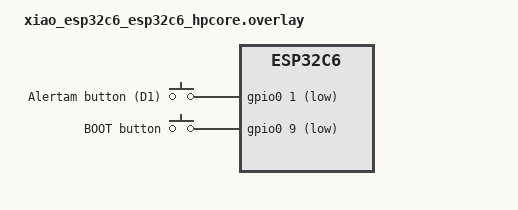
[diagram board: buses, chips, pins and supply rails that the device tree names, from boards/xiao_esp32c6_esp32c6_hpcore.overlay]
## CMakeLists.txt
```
cmake_minimum_required(VERSION 3.20.0)

find_package(Zephyr REQUIRED HINTS $ENV{ZEPHYR_BASE})
project(bitchat_esp32c6)

target_sources(app PRIVATE 
    src/main.c
    src/bitchat_crypto.c
    src/bitchat_wire.c
    src/noise_xx.c
    src/gesture.c
    src/alert_retry.c
    src/alertam.c
    src/alertam_store.c
    src/alertam_record.c
    lib/monocypher/monocypher.c
    lib/monocypher/monocypher-ed25519.c
)
```

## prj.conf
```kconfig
# Covekey Project Configuration - BitChat Bot

# Console and Logging
CONFIG_LOG=y
CONFIG_LOG_MODE_IMMEDIATE=y
CONFIG_LOG_DEFAULT_LEVEL=3
CONFIG_CONSOLE=y
CONFIG_UART_CONSOLE=y
CONFIG_SERIAL=y
CONFIG_PRINTK=y
CONFIG_EARLY_CONSOLE=y

# GPIO (required for future expansion)
CONFIG_GPIO=y

# Bluetooth LE Support
CONFIG_BT=y
CONFIG_BT_PERIPHERAL=y
CONFIG_BT_CENTRAL=y
CONFIG_BT_OBSERVER=y
CONFIG_BT_BROADCASTER=y
CONFIG_BT_DEVICE_NAME="BitChat"
CONFIG_BT_DEVICE_NAME_DYNAMIC=n
CONFIG_BT_MAX_CONN=4
CONFIG_BT_L2CAP_TX_BUF_COUNT=3
CONFIG_BT_CONN_CHECK_NULL_BEFORE_CREATE=y

# ESP32-C6 CRITICAL: Enable parallel scan and connection initiation
# bt_le_scan_stop() crashes on ESP32-C6, this allows connections while scanning
CONFIG_BT_SCAN_AND_INITIATE_IN_PARALLEL=y

# GATT Client support (for mesh messaging)
CONFIG_BT_GATT_CLIENT=y
# Alertam: find the peer's CCC descriptor instead of guessing its handle
CONFIG_BT_GATT_AUTO_DISCOVER_CCC=y

# MTU and buffer configuration
# Increased ACL buffer size to support higher ATT MTU negotiation
# ATT MTU is negotiated based on ACL buffer size, not L2CAP MTU
# 512 bytes allows ATT MTU of ~508 bytes, preventing fragmentation of TLV handshakes
CONFIG_BT_L2CAP_TX_MTU=512
CONFIG_BT_BUF_ACL_TX_SIZE=512
CONFIG_BT_BUF_ACL_RX_SIZE=512
CONFIG_BT_ATT_PREPARE_COUNT=1

# HCI buffer pool - increased for parallel scan+connect operations
CONFIG_BT_BUF_ACL_TX_COUNT=4

# BLE advertising - extended advertising required for parallel scan/initiate
# CONFIG_BT_EXT_ADV is auto-enabled by CONFIG_BT_SCAN_AND_INITIATE_IN_PARALLEL
CONFIG_BT_PRIVACY=n

# NO NETWORKING - Bluetooth only
CONFIG_NETWORKING=n

# PSA Crypto API (modern mbedTLS) for Noise XX protocol
CONFIG_MBEDTLS=y
CONFIG_MBEDTLS_BUILTIN=y
CONFIG_PSA_CRYPTO_PROVIDER_MBEDTLS=y
CONFIG_PSA_WANT_ALG_ECDH=y
CONFIG_PSA_WANT_ALG_SHA_256=y
CONFIG_PSA_WANT_ALG_HMAC=y
# Noise_XX requires ChaCha20-Poly1305, not AES-GCM
CONFIG_PSA_WANT_ALG_CHACHA20_POLY1305=y
CONFIG_PSA_WANT_KEY_TYPE_CHACHA20=y
# Noise_XX requires Curve25519 (X25519), not secp256r1
CONFIG_PSA_WANT_ECC_MONTGOMERY_255=y
CONFIG_PSA_WANT_KEY_TYPE_ECC_KEY_PAIR_IMPORT=y
CONFIG_PSA_WANT_KEY_TYPE_ECC_KEY_PAIR_EXPORT=y
CONFIG_PSA_WANT_KEY_TYPE_ECC_KEY_PAIR_GENERATE=y
CONFIG_MBEDTLS_ENABLE_HEAP=y
CONFIG_MBEDTLS_HEAP_SIZE=40960

# Shell for interactive control
CONFIG_SHELL=y
CONFIG_SHELL_BACKEND_SERIAL=y
CONFIG_SHELL_PROMPT_UART="bitchat> "
CONFIG_SHELL_CMD_BUFF_SIZE=256
CONFIG_SHELL_ARGC_MAX=12

# Memory and Threading
CONFIG_MAIN_STACK_SIZE=8192
CONFIG_SYSTEM_WORKQUEUE_STACK_SIZE=8192
CONFIG_HEAP_MEM_POOL_SIZE=65536

# ESP32-C6 BLE soft controller stability - increased buffers
CONFIG_BT_BUF_EVT_RX_COUNT=16
CONFIG_BT_BUF_CMD_TX_COUNT=8
CONFIG_BT_RX_STACK_SIZE=4096

# CRITICAL: Extended advertising/scanning buffer size limits for ESP32-C6
# When CONFIG_BT_SCAN_AND_INITIATE_IN_PARALLEL=y, BT_EXT_ADV is auto-enabled
# Extended advertising scan reports require 122 bytes for HCI event buffers
# ESP32-C6 ACL data buffers limited to 58 bytes, but event buffers can be larger
CONFIG_BT_BUF_EVT_DISCARDABLE_SIZE=122
CONFIG_BT_BUF_EVT_DISCARDABLE_COUNT=8
CONFIG_BT_BUF_EVT_RX_SIZE=122

# System
CONFIG_REBOOT=y

# Alertam persistence: identity, nickname, circle, SOS text (src/alertam_store.c)
# Zephyr settings on ZMS in storage_partition (0x3B0000). Not encrypted yet.
CONFIG_FLASH=y
CONFIG_FLASH_MAP=y
CONFIG_ZMS=y
CONFIG_SETTINGS=y
CONFIG_SETTINGS_ZMS=y
CONFIG_SETTINGS_ZMS_CUSTOM_SECTOR_COUNT=y
CONFIG_SETTINGS_ZMS_SECTOR_COUNT=8

# BLE TX power: default was 0 dBm; +9 dBm is Espressif's default (max +20).
CONFIG_BT_CTLR_TX_PWR_PLUS_9=y
```

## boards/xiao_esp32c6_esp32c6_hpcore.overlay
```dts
/*
 * Alertam buttons on the Seeed XIAO ESP32-C6.
 *
 * - alertam_btn: external tactile button between D1 (GPIO1) and GND,
 *   internal pull-up, active low. This is the "real" panic button.
 * - boot_btn: the on-board BOOT button (GPIO9, has an external pull-up).
 *   Same gestures, so the firmware can be tested without wiring anything.
 *
 * Both feed the same gesture detector (src/gesture.c).
 */
/ {
	alertam_buttons {
		compatible = "gpio-keys";

		alertam_btn: alertam_button {
			gpios = <&gpio0 1 (GPIO_ACTIVE_LOW | GPIO_PULL_UP)>;
			label = "Alertam button (D1)";
		};

		boot_btn: boot_button {
			gpios = <&gpio0 9 GPIO_ACTIVE_LOW>;
			label = "BOOT button";
		};
	};

	aliases {
		alertam-button = &alertam_btn;
		alertam-boot-button = &boot_btn;
	};
};
```

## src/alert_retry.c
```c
/*
 * alert_retry.c - retry / re-broadcast scheduling for Alertam alerts.
 * See alert_retry.h.
 */
#include "alert_retry.h"

#include <string.h>

/* ---------- public alert ---------- */

bool ar_pub_fresh(const struct ar_public *p, int64_t now)
{
	return p->have_packet && now - p->built < AR_PUB_STALE_MS;
}

void ar_pub_start(struct ar_public *p, int64_t now, bool keep_packet)
{
	if (keep_packet && p->state != AR_PUB_IDLE && ar_pub_fresh(p, now)) {
		/* Same alert again: extend it, send right away, no new chat line */
		p->started = now;
		if (p->state == AR_PUB_SENT) {
			p->first_sent = now;
		}
		p->last_try = -1;
		return;
	}
	memset(p, 0, sizeof(*p));
	p->state = AR_PUB_PENDING;
	p->started = now;
	p->last_try = -1;
}

void ar_pub_stop(struct ar_public *p)
{
	p->state = AR_PUB_IDLE;
}

enum ar_action ar_pub_poll(struct ar_public *p, int64_t now, bool can_send, bool new_link)
{
	if (p->state == AR_PUB_IDLE) {
		return AR_NONE;
	}
	if (p->state == AR_PUB_SENT && now - p->first_sent >= AR_LIFETIME_MS) {
		p->state = AR_PUB_IDLE;
		return AR_NONE;
	}
	if (!can_send) {
		return AR_NONE;
	}
	bool fresh = ar_pub_fresh(p, now);
	bool never = p->last_try < 0;

	if (p->state == AR_PUB_PENDING) {
		if (!fresh) {
			return AR_REBUILD_SEND; /* nothing cached yet, or about to go stale */
		}
		if (never || new_link || now - p->last_try >= AR_PUB_RETRY_MS) {
			return AR_SEND;
		}
		return AR_NONE;
	}
	/* SENT */
	if (fresh) {
		if (never || new_link || now - p->last_try >= AR_PUB_REBROADCAST_MS) {
			return AR_SEND;
		}
		return AR_NONE;
	}
	/* Re-broadcast window over: only a phone that just came into range is
	 * worth a new (re-signed) packet */
	return new_link || never ? AR_REBUILD_SEND : AR_NONE;
}

void ar_pub_built(struct ar_public *p, int64_t now)
{
	p->have_packet = true;
	p->built = now;
	p->builds++;
}

bool ar_pub_wrote(struct ar_public *p, int64_t now, bool ok)
{
	p->last_try = now;
	if (!ok) {
		return false;
	}
	p->writes++;
	if (p->state == AR_PUB_PENDING) {
		p->state = AR_PUB_SENT;
		p->first_sent = now;
		return true;
	}
	return false;
}

/* ---------- private SOS ---------- */

int64_t ar_pm_backoff(uint32_t n)
{
	int64_t d = AR_PM_BACKOFF_MIN_MS;
	for (uint32_t i = 1; i < n && d < AR_PM_BACKOFF_MAX_MS; i++) {
		d *= 2;
	}
	return d > AR_PM_BACKOFF_MAX_MS ? AR_PM_BACKOFF_MAX_MS : d;
}

static bool undelivered(const struct ar_rcpt *r)
{
	return r->state == AR_RCPT_PENDING || r->state == AR_RCPT_SENT;
}

void ar_priv_start(struct ar_private *p, int64_t now, int n)
{
	memset(p, 0, sizeof(*p));
	p->n = n > AR_MAX_RCPT ? AR_MAX_RCPT : (n < 0 ? 0 : n);
	p->active = p->n > 0;
	p->started = now;
	for (int i = 0; i < p->n; i++) {
		p->r[i].state = AR_RCPT_PENDING;
		p->r[i].next = now;
		p->r[i].last_try = -1;
	}
}

void ar_priv_restart(struct ar_private *p, int64_t now)
{
	p->started = now;
	for (int i = 0; i < p->n; i++) {
		struct ar_rcpt *r = &p->r[i];
		if (r->state == AR_RCPT_EXPIRED) {
			r->state = r->attempts ? AR_RCPT_SENT : AR_RCPT_PENDING;
		}
		if (undelivered(r)) {
			r->next = now;
			r->attempts = 0; /* backoff starts over */
		}
	}
	p->active = ar_priv_count(p, AR_RCPT_PENDING) + ar_priv_count(p, AR_RCPT_SENT) > 0;
}

void ar_priv_stop(struct ar_private *p)
{
	p->active = false;
}

int ar_priv_tick(struct ar_private *p, int64_t now)
{
	if (!p->active) {
		return 0;
	}
	int expired = 0;
	if (now - p->started >= AR_LIFETIME_MS) {
		for (int i = 0; i < p->n; i++) {
			if (undelivered(&p->r[i])) {
				p->r[i].state = AR_RCPT_EXPIRED;
				expired++;
			}
		}
	}
	bool left = false;
	for (int i = 0; i < p->n; i++) {
		left |= undelivered(&p->r[i]);
	}
	p->active = left;
	return expired;
}

bool ar_priv_due(const struct ar_private *p, int i, int64_t now, bool can_send)
{
	return p->active && can_send && i >= 0 && i < p->n && undelivered(&p->r[i]) &&
	       now >= p->r[i].next;
}

void ar_priv_attempted(struct ar_private *p, int i, int64_t now, bool ok)
{
	struct ar_rcpt *r = &p->r[i];
	r->last_try = now;
	if (ok) {
		r->attempts++;
		if (r->state == AR_RCPT_PENDING) {
			r->state = AR_RCPT_SENT;
		}
		r->next = now + ar_pm_backoff(r->attempts);
	} else {
		/* local failure (link dropped, encrypt error): short retry, no backoff */
		r->failures++;
		r->next = now + AR_PM_BACKOFF_MIN_MS;
	}
}

void ar_priv_link_up(struct ar_private *p, int64_t now)
{
	for (int i = 0; p->active && i < p->n; i++) {
		struct ar_rcpt *r = &p->r[i];
		if (undelivered(r) && r->next > now &&
		    (r->last_try < 0 || now - r->last_try >= AR_PM_KICK_GAP_MS)) {
			r->next = now;
		}
	}
}

bool ar_priv_ack(struct ar_private *p, int i, int64_t now)
{
	if (i < 0 || i >= p->n || p->r[i].state == AR_RCPT_DELIVERED ||
	    p->r[i].state == AR_RCPT_UNUSED) {
		return false;
	}
	/* A late ACK after expiry still counts: the message did arrive */
	p->r[i].state = AR_RCPT_DELIVERED;
	p->r[i].delivered_at = now;
	return true;
}

int64_t ar_priv_next_due(const struct ar_private *p)
{
	int64_t best = -1;
	for (int i = 0; p->active && i < p->n; i++) {
		if (undelivered(&p->r[i]) && (best < 0 || p->r[i].next < best)) {
			best = p->r[i].next;
		}
	}
	return best;
}

int ar_priv_count(const struct ar_private *p, enum ar_rcpt_state s)
{
	int c = 0;
	for (int i = 0; i < p->n; i++) {
		c += p->r[i].state == s;
	}
	return c;
}

const char *ar_pub_state_name(enum ar_pub_state s)
{
	switch (s) {
	case AR_PUB_PENDING: return "pending";
	case AR_PUB_SENT:    return "sent";
	default:             return "idle";
	}
}

const char *ar_rcpt_state_name(enum ar_rcpt_state s)
{
	switch (s) {
	case AR_RCPT_PENDING:   return "pending";
	case AR_RCPT_SENT:      return "sent, waiting ACK";
	case AR_RCPT_DELIVERED: return "delivered";
	case AR_RCPT_EXPIRED:   return "EXPIRED";
	default:                return "-";
	}
}
```

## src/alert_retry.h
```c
/*
 * alert_retry.h - retry / re-broadcast scheduling for Alertam alerts
 *
 * Pure state machines (no Zephyr, no I/O): the caller feeds a millisecond
 * clock and whether it can send right now (a link is ready and the wall clock
 * is synced), and gets back what to do. Unit-tested on the host
 * (tests/test_alert_retry.c).
 *
 * Public alert (signed broadcast, no ACK exists):
 *   PENDING  nothing written to any link yet. Retry every AR_PUB_RETRY_MS and
 *            on every new link; rebuild the signed packet whenever the cached
 *            one is AR_PUB_STALE_MS old (the app rejects |skew| > 120 s).
 *   SENT     written to at least one link. Re-send the same cached bytes every
 *            AR_PUB_REBROADCAST_MS until the cache is stale (the app dedups
 *            identical packets, so phones that already have it see nothing new).
 *            After that, only a new link triggers a rebuild + send (a rebuild is
 *            a new chat line). Ends AR_LIFETIME_MS after the first write.
 *   A PENDING alert never expires: it must go out at least once.
 *
 * Private SOS (Noise PM per circle member, the app ACKs with the messageID):
 *   PENDING -> SENT (written, waiting for the ACK) -> DELIVERED, or EXPIRED
 *   AR_LIFETIME_MS after the SOS started. Undelivered recipients are retried
 *   with backoff 5, 10, 20, 30, 30... s, each one on its own schedule.
 */
#ifndef ALERT_RETRY_H
#define ALERT_RETRY_H

#include <stdbool.h>
#include <stdint.h>

#define AR_PUB_RETRY_MS        5000
#define AR_PUB_REBROADCAST_MS 20000
#define AR_PUB_STALE_MS      100000
#define AR_LIFETIME_MS       600000
#define AR_PM_BACKOFF_MIN_MS   5000
#define AR_PM_BACKOFF_MAX_MS  30000
#define AR_PM_KICK_GAP_MS      2000 /* min gap between attempts when a link comes up */
#define AR_MAX_RCPT 5

enum ar_action {
	AR_NONE = 0,
	AR_SEND,         /* write the cached packet */
	AR_REBUILD_SEND, /* build a fresh signed packet, cache it, write it */
};

/* ---------- public alert ---------- */

enum ar_pub_state {
	AR_PUB_IDLE = 0,
	AR_PUB_PENDING,
	AR_PUB_SENT,
};

struct ar_public {
	enum ar_pub_state state;
	bool have_packet;
	int64_t started;    /* trigger time */
	int64_t built;      /* build time of the cached packet */
	int64_t first_sent; /* first successful write (lifetime anchor) */
	int64_t last_try;   /* last write attempt, -1 = none since (re)start */
	uint32_t writes;    /* successful writes */
	uint32_t builds;
};

/* Start an alert. keep_packet: a re-trigger with the same text keeps a still
 * fresh cached packet (no duplicate chat line) and just refreshes the lifetime
 * and forces an immediate send. */
void ar_pub_start(struct ar_public *p, int64_t now, bool keep_packet);
void ar_pub_stop(struct ar_public *p);
/* Decide what to do now. new_link: a link just became usable. Also ends the
 * alert when its lifetime is over (state goes back to IDLE). */
enum ar_action ar_pub_poll(struct ar_public *p, int64_t now, bool can_send, bool new_link);
void ar_pub_built(struct ar_public *p, int64_t now);
/* Result of the write the last poll asked for. Returns true on the first
 * successful write (PENDING -> SENT). */
bool ar_pub_wrote(struct ar_public *p, int64_t now, bool ok);
bool ar_pub_fresh(const struct ar_public *p, int64_t now);

/* ---------- private SOS ---------- */

enum ar_rcpt_state {
	AR_RCPT_UNUSED = 0,
	AR_RCPT_PENDING,   /* never written */
	AR_RCPT_SENT,      /* written at least once, no ACK yet */
	AR_RCPT_DELIVERED, /* ACK received */
	AR_RCPT_EXPIRED,   /* lifetime over without an ACK */
};

struct ar_rcpt {
	enum ar_rcpt_state state;
	uint32_t attempts;  /* successful writes */
	uint32_t failures;  /* writes that failed locally */
	int64_t next;       /* next attempt due at */
	int64_t last_try;
	int64_t delivered_at;
};

struct ar_private {
	bool active;
	int64_t started;
	int n;
	struct ar_rcpt r[AR_MAX_RCPT];
};

/* Backoff after the n-th successful attempt (n >= 1) */
int64_t ar_pm_backoff(uint32_t n);

void ar_priv_start(struct ar_private *p, int64_t now, int n);
/* Re-trigger: refresh the lifetime and make every undelivered recipient due now */
void ar_priv_restart(struct ar_private *p, int64_t now);
void ar_priv_stop(struct ar_private *p);
/* Lifetime / completion bookkeeping. Returns the number of recipients that
 * just expired (so the caller can log them). Clears active when done. */
int ar_priv_tick(struct ar_private *p, int64_t now);
bool ar_priv_due(const struct ar_private *p, int i, int64_t now, bool can_send);
void ar_priv_attempted(struct ar_private *p, int i, int64_t now, bool ok);
/* A link came up: pull undelivered retries forward (not more often than
 * AR_PM_KICK_GAP_MS per recipient). */
void ar_priv_link_up(struct ar_private *p, int64_t now);
/* ACK for recipient i. Returns true if this is the first one. */
bool ar_priv_ack(struct ar_private *p, int i, int64_t now);
/* Earliest time any undelivered recipient is due (or -1 if none) */
int64_t ar_priv_next_due(const struct ar_private *p);
int ar_priv_count(const struct ar_private *p, enum ar_rcpt_state s);

const char *ar_pub_state_name(enum ar_pub_state s);
const char *ar_rcpt_state_name(enum ar_rcpt_state s);

#endif /* ALERT_RETRY_H */
```

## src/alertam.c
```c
/*
 * alertam.c - Alertam panic-button behavior. See alertam.h.
 */
#include "alertam.h"

#include <string.h>
#include <zephyr/drivers/gpio.h>
#include <stdlib.h>
#include <zephyr/init.h>
#include <esp_bt.h>
#include <zephyr/shell/shell.h>
#include <zephyr/sys/printk.h>

#include "alert_retry.h"
#include "alertam_store.h"
#include "bitchat_wire.h"
#include "gesture.h"

#define CIRCLE_MAX 5
#define POLL_MS 10

static const struct gpio_dt_spec btn_ext = GPIO_DT_SPEC_GET(DT_ALIAS(alertam_button), gpios);
static const struct gpio_dt_spec btn_boot = GPIO_DT_SPEC_GET(DT_ALIAS(alertam_boot_button), gpios);
static const struct gpio_dt_spec led = GPIO_DT_SPEC_GET(DT_ALIAS(led0), gpios);

static struct k_work_q *ble_q;
static alertam_links_fn links_ready;

static char sos_text[200] = "SOS - Alertam: necesito ayuda";

static struct {
	bool used;
	char name[24];  /* nickname at the time it was added */
	char id_hex[17];
} circle[CIRCLE_MAX];

/* ---------- alerts (run on the BLE work queue) ----------
 *
 * Nothing is fire-and-forget: both alerts stay active and are retried by
 * retry_work (1 s tick while anything is active) until delivered, see
 * alert_retry.h for the rules. State is shared with the shell ('sos status',
 * 'sos cancel'), hence alert_lock. */

#define RETRY_TICK_MS 1000

BUILD_ASSERT(CIRCLE_MAX <= AR_MAX_RCPT, "one SOS recipient slot per circle member");

static K_MUTEX_DEFINE(alert_lock);
static atomic_t link_kick; /* a link became usable since the last tick */

static struct ar_public pub;
static char pub_text[sizeof(sos_text)];  /* text the cached packet carries */
static uint8_t pub_pkt[BCW_MAX_PACKET];
static int pub_len;

static struct ar_private priv;
static char priv_text[sizeof(sos_text)];
static struct {
	char name[24];
	char id_hex[17];
	uint8_t id[8];
	char msg_id[37]; /* one per SOS: retries are deduped by the app */
} rcpt[AR_MAX_RCPT];

static void retry_handler(struct k_work *work);
static K_WORK_DELAYABLE_DEFINE(retry_work, retry_handler);

static bool can_send(void)
{
	return bcw_clock_synced() && links_ready && links_ready() > 0;
}

static const char *why_not(void)
{
	return !bcw_clock_synced() ? "no phone seen yet (clock not synced)" : "no phone in range";
}

static void led_confirm(void);

static void public_step(int64_t now, bool ok_to_send, bool new_link)
{
	enum ar_pub_state before = pub.state;
	enum ar_action a = ar_pub_poll(&pub, now, ok_to_send, new_link);

	if (before == AR_PUB_SENT && pub.state == AR_PUB_IDLE) {
		printk("[Alertam] PUBLIC alert finished (%u writes, %u packets, %d min active)\n",
		       pub.writes, pub.builds, AR_LIFETIME_MS / 60000);
		return;
	}
	if (a == AR_NONE) {
		return;
	}
	if (a == AR_REBUILD_SEND) {
		int n = bcw_build_public_message(pub_text, pub_pkt, sizeof(pub_pkt));
		if (n < 0) {
			printk("[Alertam] PUBLIC alert: cannot build packet (%d), dropped\n", n);
			ar_pub_stop(&pub);
			return;
		}
		pub_len = n;
		if (pub.builds > 0) {
			printk("[Alertam] PUBLIC alert re-signed (%s)\n", pub.state == AR_PUB_PENDING
			       ? "cached packet about to go stale" : "phone came into range");
		}
		ar_pub_built(&pub, now);
	}
	int ret = bcw_broadcast(pub_pkt, (uint16_t)pub_len);
	if (ar_pub_wrote(&pub, now, ret == 0)) {
		printk("[Alertam] PUBLIC alert sent (pending %lld s): \"%s\" - re-broadcasting "
		       "every %d s for %d s\n", (now - pub.started) / 1000, pub_text,
		       AR_PUB_REBROADCAST_MS / 1000, AR_PUB_STALE_MS / 1000);
		led_confirm();
	} else if (ret == 0) {
		printk("[Alertam] PUBLIC alert re-broadcast #%u (packet age %lld s)\n",
		       pub.writes - 1, (now - pub.built) / 1000);
	} else {
		printk("[Alertam] PUBLIC alert write failed (%d), retry in %d s\n", ret,
		       AR_PUB_RETRY_MS / 1000);
	}
}

static void private_step(int64_t now, bool ok_to_send, bool new_link)
{
	if (!priv.active) {
		return;
	}
	if (ar_priv_tick(&priv, now) > 0) {
		for (int i = 0; i < priv.n; i++) {
			if (priv.r[i].state == AR_RCPT_EXPIRED) {
				printk("[Alertam] private SOS -> %s: NOT delivered after %u attempts, "
				       "giving up\n", rcpt[i].name, priv.r[i].attempts);
			}
		}
	}
	if (new_link) {
		ar_priv_link_up(&priv, now);
	}
	for (int i = 0; i < priv.n; i++) {
		if (!ar_priv_due(&priv, i, now, ok_to_send)) {
			continue;
		}
		/* one failing member must not block the others */
		int ret = bcw_send_private_with_id(rcpt[i].id_hex, priv_text, rcpt[i].msg_id);
		ar_priv_attempted(&priv, i, now, ret == 0);
		printk("[Alertam] private SOS -> %s: attempt %u %s, next in %lld s\n", rcpt[i].name,
		       priv.r[i].attempts + priv.r[i].failures,
		       ret == 0 ? "sent/queued" : "failed", (priv.r[i].next - now) / 1000);
	}
}

static void retry_handler(struct k_work *work)
{
	int64_t now = k_uptime_get();
	bool new_link = atomic_clear(&link_kick) != 0;
	bool ok_to_send = can_send();

	k_mutex_lock(&alert_lock, K_FOREVER);
	public_step(now, ok_to_send, new_link);
	private_step(now, ok_to_send, new_link);
	bool active = pub.state != AR_PUB_IDLE || priv.active;
	k_mutex_unlock(&alert_lock);

	if (active) {
		k_work_reschedule_for_queue(ble_q, &retry_work, K_MSEC(RETRY_TICK_MS));
	}
}

static void public_alert_handler(struct k_work *work)
{
	int64_t now = k_uptime_get();
	k_mutex_lock(&alert_lock, K_FOREVER);
	bool same = pub.state != AR_PUB_IDLE && strcmp(pub_text, sos_text) == 0;
	if (pub.state != AR_PUB_IDLE) {
		printk("[Alertam] PUBLIC alert re-triggered (%s)\n",
		       same && ar_pub_fresh(&pub, now) ? "same packet, lifetime refreshed"
						       : "new packet");
	}
	ar_pub_start(&pub, now, same);
	strcpy(pub_text, sos_text);
	if (!can_send()) {
		printk("[Alertam] PUBLIC alert pending (%s): \"%s\"\n", why_not(), pub_text);
	}
	k_mutex_unlock(&alert_lock);
	k_work_reschedule_for_queue(ble_q, &retry_work, K_NO_WAIT);
}

/* Is the active SOS for the same text and the same circle? */
static bool same_sos(void)
{
	int n = 0;
	if (!priv.active || strcmp(priv_text, sos_text) != 0) {
		return false;
	}
	for (int i = 0; i < CIRCLE_MAX; i++) {
		if (!circle[i].used) {
			continue;
		}
		bool found = false;
		for (int j = 0; j < priv.n && !found; j++) {
			found = strcmp(rcpt[j].id_hex, circle[i].id_hex) == 0;
		}
		if (!found) {
			return false;
		}
		n++;
	}
	return n == priv.n;
}

static void private_sos_handler(struct k_work *work)
{
	int64_t now = k_uptime_get();
	k_mutex_lock(&alert_lock, K_FOREVER);
	if (same_sos()) {
		ar_priv_restart(&priv, now);
		printk("[Alertam] private SOS re-triggered: %d undelivered retried now\n",
		       ar_priv_count(&priv, AR_RCPT_PENDING) + ar_priv_count(&priv, AR_RCPT_SENT));
	} else {
		/* New SOS: snapshot the circle and the text, one messageID each */
		int n = 0;
		for (int i = 0; i < CIRCLE_MAX; i++) {
			if (!circle[i].used || bcw_lookup_peer(circle[i].id_hex, rcpt[n].id) != 0) {
				continue;
			}
			snprintk(rcpt[n].name, sizeof(rcpt[n].name), "%s", circle[i].name);
			snprintk(rcpt[n].id_hex, sizeof(rcpt[n].id_hex), "%s", circle[i].id_hex);
			bcw_new_message_id(rcpt[n].msg_id);
			n++;
		}
		ar_priv_start(&priv, now, n);
		strcpy(priv_text, sos_text);
		if (n == 0) {
			printk("[Alertam] private SOS: circle is empty (use 'circle add <nick>')\n");
		} else if (!can_send()) {
			printk("[Alertam] private SOS to %d recipient(s) pending (%s)\n", n, why_not());
		} else {
			printk("[Alertam] private SOS to %d recipient(s)\n", n);
		}
	}
	k_mutex_unlock(&alert_lock);
	k_work_reschedule_for_queue(ble_q, &retry_work, K_NO_WAIT);
}

/* Delivered ACK / read receipt from bitchat_wire (BLE work queue) */
static void on_delivered(const uint8_t peer_id[8], const char *msg_id)
{
	int64_t now = k_uptime_get();
	k_mutex_lock(&alert_lock, K_FOREVER);
	for (int i = 0; i < priv.n; i++) {
		if (memcmp(rcpt[i].id, peer_id, 8) != 0 || strcmp(rcpt[i].msg_id, msg_id) != 0) {
			continue;
		}
		if (ar_priv_ack(&priv, i, now)) {
			printk("[Alertam] private SOS -> %s: delivered (%u attempt(s), %lld s)\n",
			       rcpt[i].name, priv.r[i].attempts, (now - priv.started) / 1000);
			if (ar_priv_count(&priv, AR_RCPT_DELIVERED) == priv.n) {
				printk("[Alertam] private SOS: all %d recipient(s) delivered\n", priv.n);
			}
			led_confirm();
		}
		break;
	}
	k_mutex_unlock(&alert_lock);
}

void alertam_link_ready(void)
{
	if (!ble_q) {
		return;
	}
	atomic_set(&link_kick, 1);
	k_work_reschedule_for_queue(ble_q, &retry_work, K_NO_WAIT);
}

static K_WORK_DEFINE(public_alert_work, public_alert_handler);
static K_WORK_DEFINE(private_sos_work, private_sos_handler);

/* ---------- LED feedback ---------- */

static void led_blink(int times, int on_ms, int off_ms)
{
	for (int i = 0; i < times; i++) {
		gpio_pin_set_dt(&led, 1);
		k_msleep(on_ms);
		gpio_pin_set_dt(&led, 0);
		if (i + 1 < times) {
			k_msleep(off_ms);
		}
	}
}

/* Short blink when a delivery is first confirmed. Called from the BLE queue,
 * so it must not sleep: the system work queue turns the LED off. */
static void led_off_handler(struct k_work *work)
{
	gpio_pin_set_dt(&led, 0);
}
static K_WORK_DELAYABLE_DEFINE(led_off_work, led_off_handler);

static void led_confirm(void)
{
	gpio_pin_set_dt(&led, 1);
	k_work_reschedule(&led_off_work, K_MSEC(200));
}

/* ---------- button thread ---------- */

static void button_thread(void *a, void *b, void *c)
{
	struct gesture_state st;
	const struct gesture_cfg cfg = GESTURE_CFG_DEFAULT;
	gesture_init(&st);

	while (1) {
		bool pressed = gpio_pin_get_dt(&btn_ext) > 0 || gpio_pin_get_dt(&btn_boot) > 0;
		enum gesture g = gesture_update(&st, &cfg, pressed, k_uptime_get_32());

		switch (g) {
		case GESTURE_LONG:
			printk("[Button] long press -> PUBLIC alert\n");
			k_work_submit_to_queue(ble_q, &public_alert_work);
			led_blink(1, 1500, 0);
			break;
		case GESTURE_DOUBLE:
			printk("[Button] double tap -> PRIVATE SOS\n");
			k_work_submit_to_queue(ble_q, &private_sos_work);
			led_blink(3, 120, 120);
			break;
		case GESTURE_SINGLE:
			printk("[Button] single tap (no action)\n");
			break;
		default:
			break;
		}
		k_msleep(POLL_MS);
	}
}

/* ---------- persistence (alertam_store.c) ---------- */

static void circle_save(const struct shell *sh)
{
	struct arec_member m[CIRCLE_MAX];
	int n = 0;
	for (int i = 0; i < CIRCLE_MAX; i++) {
		if (circle[i].used) {
			memcpy(m[n].name, circle[i].name, sizeof(m[n].name));
			memcpy(m[n].id_hex, circle[i].id_hex, sizeof(m[n].id_hex));
			n++;
		}
	}
	if (astore_save_circle(m, n) != 0) {
		shell_warn(sh, "Circle NOT saved to flash (kept in RAM until reboot)");
	}
}

static void persisted_load(void)
{
	struct arec_member m[CIRCLE_MAX];
	int n = astore_load_circle(m, CIRCLE_MAX);
	for (int i = 0; i < n; i++) {
		circle[i].used = true;
		memcpy(circle[i].name, m[i].name, sizeof(circle[i].name));
		memcpy(circle[i].id_hex, m[i].id_hex, sizeof(circle[i].id_hex));
	}
	const char *text = astore_sos();
	if (text) {
		strncpy(sos_text, text, sizeof(sos_text) - 1);
	}
	printk("[Alertam] Loaded %d circle member(s), SOS text %s\n", n,
	       text ? "from flash" : "default");
}

/*
 * XIAO ESP32-C6 RF switch: GPIO3 enables it, GPIO14 selects the antenna
 * (low = on-board ceramic). Zephyr's board.c only drives these when
 * CONFIG_XIAO_ESP32C6_EXT_ANTENNA is set, so with the internal antenna the
 * switch stayed off and BLE range was ~1 m. Drive it ourselves, before BT.
 */
#if DT_NODE_HAS_STATUS_OKAY(DT_NODELABEL(rf_switch)) && !defined(CONFIG_XIAO_ESP32C6_EXT_ANTENNA)
static int alertam_rf_switch_init(void)
{
	const struct gpio_dt_spec en = GPIO_DT_SPEC_GET(DT_NODELABEL(rf_switch), enable_gpios);
	const struct gpio_dt_spec sel = GPIO_DT_SPEC_GET(DT_NODELABEL(rf_switch), select_gpios);

	if (gpio_is_ready_dt(&en)) {
		gpio_pin_configure_dt(&en, GPIO_OUTPUT_ACTIVE);
	}
	if (gpio_is_ready_dt(&sel)) {
		gpio_pin_configure_dt(&sel, GPIO_OUTPUT_INACTIVE);
	}
	return 0;
}
SYS_INIT(alertam_rf_switch_init, POST_KERNEL, CONFIG_APPLICATION_INIT_PRIORITY);
#endif

K_THREAD_STACK_DEFINE(button_stack, 1536);
static struct k_thread button_tid;

int alertam_init(struct k_work_q *q, alertam_links_fn links_fn)
{
	ble_q = q;
	links_ready = links_fn;
	bcw_set_delivered_cb(on_delivered);
	persisted_load();

	if (!gpio_is_ready_dt(&btn_ext) || !gpio_is_ready_dt(&btn_boot) || !gpio_is_ready_dt(&led)) {
		printk("[Alertam] GPIO not ready\n");
		return -ENODEV;
	}
	gpio_pin_configure_dt(&btn_ext, GPIO_INPUT);
	gpio_pin_configure_dt(&btn_boot, GPIO_INPUT);
	gpio_pin_configure_dt(&led, GPIO_OUTPUT_INACTIVE);

	k_thread_create(&button_tid, button_stack, K_THREAD_STACK_SIZEOF(button_stack),
			button_thread, NULL, NULL, NULL, 7, 0, K_NO_WAIT);
	k_thread_name_set(&button_tid, "alertam_btn");
	printk("[Alertam] Buttons ready: D1 + BOOT (hold 2 s = public, double tap = private SOS)\n");
	return 0;
}

/* ---------- shell ---------- */

static int cmd_sos_text(const struct shell *sh, size_t argc, char **argv)
{
	if (argc < 2) {
		shell_print(sh, "SOS text: \"%s\"", sos_text);
		return 0;
	}
	size_t pos = 0;
	for (size_t a = 1; a < argc && pos < sizeof(sos_text) - 1; a++) {
		int w = snprintk(sos_text + pos, sizeof(sos_text) - pos, "%s%s", a > 1 ? " " : "", argv[a]);
		if (w < 0) {
			break;
		}
		pos = MIN(pos + (size_t)w, sizeof(sos_text) - 1);
	}
	shell_print(sh, "SOS text set: \"%s\"", sos_text);
	if (astore_save_sos(sos_text) != 0) {
		shell_warn(sh, "SOS text NOT saved to flash");
	}
	return 0;
}

static int cmd_sos_public(const struct shell *sh, size_t argc, char **argv)
{
	k_work_submit_to_queue(ble_q, &public_alert_work);
	return 0;
}

static int cmd_sos_private(const struct shell *sh, size_t argc, char **argv)
{
	k_work_submit_to_queue(ble_q, &private_sos_work);
	return 0;
}

static int cmd_sos_status(const struct shell *sh, size_t argc, char **argv)
{
	int64_t now = k_uptime_get();
	k_mutex_lock(&alert_lock, K_FOREVER);
	shell_print(sh, "Links ready: %d, clock %s", links_ready ? links_ready() : 0,
		    bcw_clock_synced() ? "synced" : "NOT synced");
	if (pub.state == AR_PUB_IDLE) {
		shell_print(sh, "PUBLIC: idle");
	} else {
		shell_print(sh, "PUBLIC: %s for %lld s, %u write(s), %u packet(s)%s \"%s\"",
			    ar_pub_state_name(pub.state), (now - pub.started) / 1000, pub.writes,
			    pub.builds, ar_pub_fresh(&pub, now) ? " (re-broadcasting)" : "", pub_text);
		if (pub.state == AR_PUB_SENT) {
			shell_print(sh, "  ends in %lld s",
				    (pub.first_sent + AR_LIFETIME_MS - now) / 1000);
		}
	}
	if (priv.n == 0) {
		shell_print(sh, "PRIVATE: none");
	} else {
		shell_print(sh, "PRIVATE: %s, started %lld s ago, %d/%d delivered \"%s\"",
			    priv.active ? "active" : "done", (now - priv.started) / 1000,
			    ar_priv_count(&priv, AR_RCPT_DELIVERED), priv.n, priv_text);
		for (int i = 0; i < priv.n; i++) {
			const struct ar_rcpt *r = &priv.r[i];
			bool waiting = r->state == AR_RCPT_PENDING || r->state == AR_RCPT_SENT;
			char next[40] = "";

			if (waiting) {
				snprintk(next, sizeof(next), ", next in %lld s",
					 (long long)(MAX(0, r->next - now) / 1000));
			}
			shell_print(sh, "  %-12s %s  %s, %u attempt(s), %u failure(s)%s",
				    rcpt[i].name, rcpt[i].id_hex, ar_rcpt_state_name(r->state),
				    r->attempts, r->failures, next);
		}
	}
	k_mutex_unlock(&alert_lock);
	return 0;
}

static int cmd_sos_cancel(const struct shell *sh, size_t argc, char **argv)
{
	k_mutex_lock(&alert_lock, K_FOREVER);
	ar_pub_stop(&pub);
	ar_priv_stop(&priv);
	k_mutex_unlock(&alert_lock);
	printk("[Alertam] alerts cancelled from the shell\n");
	return 0;
}

static int cmd_circle_add(const struct shell *sh, size_t argc, char **argv)
{
	uint8_t id[8];
	if (argc < 2 || bcw_lookup_peer(argv[1], id) != 0) {
		shell_error(sh, "Unknown peer (needs a nickname from 'list' or a 16-hex peer ID)");
		return -ENOENT;
	}
	char hex[17];
	for (int i = 0; i < 8; i++) {
		snprintk(hex + 2 * i, 3, "%02x", id[i]);
	}
	int free_slot = -1;
	for (int i = 0; i < CIRCLE_MAX; i++) {
		if (circle[i].used && strcmp(circle[i].id_hex, hex) == 0) {
			shell_print(sh, "%s is already in the circle", argv[1]);
			return 0;
		}
		if (!circle[i].used && free_slot < 0) {
			free_slot = i;
		}
	}
	if (free_slot < 0) {
		shell_error(sh, "Circle is full (%d)", CIRCLE_MAX);
		return -ENOMEM;
	}
	circle[free_slot].used = true;
	strncpy(circle[free_slot].name, argv[1], sizeof(circle[free_slot].name) - 1);
	memcpy(circle[free_slot].id_hex, hex, sizeof(hex));
	shell_print(sh, "Added %s (%s) to the circle", argv[1], hex);
	circle_save(sh);
	return 0;
}

static int cmd_circle_del(const struct shell *sh, size_t argc, char **argv)
{
	for (int i = 0; argc >= 2 && i < CIRCLE_MAX; i++) {
		if (circle[i].used && (strcmp(circle[i].name, argv[1]) == 0 ||
				       strcmp(circle[i].id_hex, argv[1]) == 0)) {
			circle[i].used = false;
			shell_print(sh, "Removed %s", argv[1]);
			circle_save(sh);
			return 0;
		}
	}
	shell_error(sh, "Not in the circle");
	return -ENOENT;
}

static int cmd_circle_list(const struct shell *sh, size_t argc, char **argv)
{
	int n = 0;
	for (int i = 0; i < CIRCLE_MAX; i++) {
		if (circle[i].used) {
			shell_print(sh, "  %s  %s", circle[i].id_hex, circle[i].name);
			n++;
		}
	}
	shell_print(sh, "%d member(s) (saved in flash)", n);
	return 0;
}

static int cmd_sos_buttons(const struct shell *sh, size_t argc, char **argv)
{
	/* Sample both buttons for 5 s and report raw levels / presses seen */
	int ext_pressed = 0, boot_pressed = 0;
	for (int i = 0; i < 500; i++) {
		ext_pressed += gpio_pin_get_dt(&btn_ext) > 0;
		boot_pressed += gpio_pin_get_dt(&btn_boot) > 0;
		k_msleep(10);
	}
	shell_print(sh, "5 s sample (10 ms): D1 pressed %d/500, BOOT pressed %d/500",
		    ext_pressed, boot_pressed);
	return 0;
}

SHELL_STATIC_SUBCMD_SET_CREATE(sub_sos,
	SHELL_CMD(buttons, NULL, "Sample button levels for 5 s (wiring check)", cmd_sos_buttons),
	SHELL_CMD(text, NULL, "[text] - Show/set the alert text", cmd_sos_text),
	SHELL_CMD(public, NULL, "Fire the public alert (same as long press)", cmd_sos_public),
	SHELL_CMD(private, NULL, "Fire the private SOS (same as double tap)", cmd_sos_private),
	SHELL_CMD(status, NULL, "Active alerts and per-recipient delivery state", cmd_sos_status),
	SHELL_CMD(cancel, NULL, "Stop retrying all active alerts", cmd_sos_cancel),
	SHELL_SUBCMD_SET_END
);
SHELL_CMD_REGISTER(sos, &sub_sos, "Alertam alerts", NULL);

/* BLE TX power at runtime (range tests). The ESP controller takes an
 * esp_power_level_t index: -24..+18 dBm in 3 dB steps, then +20. Boot default
 * comes from CONFIG_BT_CTLR_TX_PWR_* (+9 dBm); this setting is not saved. */
static int dbm_to_level(int dbm)
{
	if (dbm == 20) {
		return ESP_PWR_LVL_P20;
	}
	if (dbm < -24 || dbm > 18 || (dbm + 24) % 3 != 0) {
		return -1;
	}
	return (dbm + 24) / 3;
}

static int level_to_dbm(int lvl)
{
	return lvl == ESP_PWR_LVL_P20 ? 20 : lvl * 3 - 24;
}

static int cmd_txpower(const struct shell *sh, size_t argc, char **argv)
{
	if (argc >= 2) {
		int lvl = dbm_to_level(atoi(argv[1]));

		if (lvl < 0) {
			shell_error(sh, "Use -24..18 in steps of 3, or 20 (dBm)");
			return -EINVAL;
		}
		int err = esp_ble_tx_power_set(ESP_BLE_PWR_TYPE_DEFAULT, lvl);

		err |= esp_ble_tx_power_set(ESP_BLE_PWR_TYPE_ADV, lvl);
		err |= esp_ble_tx_power_set(ESP_BLE_PWR_TYPE_SCAN, lvl);
		/* Live links: handles without a connection just fail, ignore them */
		for (int h = ESP_BLE_PWR_TYPE_CONN_HDL0; h <= ESP_BLE_PWR_TYPE_CONN_HDL8; h++) {
			(void)esp_ble_tx_power_set(h, lvl);
		}
		if (err) {
			shell_error(sh, "Controller rejected the setting");
			return -EIO;
		}
	}
	int d = esp_ble_tx_power_get(ESP_BLE_PWR_TYPE_DEFAULT);
	int a = esp_ble_tx_power_get(ESP_BLE_PWR_TYPE_ADV);
	int c = esp_ble_tx_power_get(ESP_BLE_PWR_TYPE_CONN_HDL0);

	shell_print(sh, "TX power: default %+d dBm, adv %+d dBm, link0 %s%d dBm (not saved; reboot = +9)",
		    level_to_dbm(d), level_to_dbm(a),
		    c == ESP_PWR_LVL_INVALID ? "n/a " : (c >= 8 ? "+" : ""),
		    c == ESP_PWR_LVL_INVALID ? 0 : level_to_dbm(c));
	return 0;
}
SHELL_CMD_REGISTER(txpower, NULL, "[dBm] - Show/set BLE TX power (-24..18 step 3, or 20)", cmd_txpower);

SHELL_STATIC_SUBCMD_SET_CREATE(sub_circle,
	SHELL_CMD(add, NULL, "<nick|peer-id> - Add to the private SOS circle", cmd_circle_add),
	SHELL_CMD(del, NULL, "<nick|peer-id> - Remove", cmd_circle_del),
	SHELL_CMD(list, NULL, "List circle members", cmd_circle_list),
	SHELL_SUBCMD_SET_END
);
SHELL_CMD_REGISTER(circle, &sub_circle, "Pre-approved private SOS circle", NULL);
```

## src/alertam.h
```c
/*
 * alertam.h - Alertam panic-button behavior on top of bitchat
 *
 * Buttons (D1 external + on-board BOOT, see the board overlay in boards/) feed the
 * gesture detector:
 *   long press (>= 2 s) -> public alert: signed BitChat public message
 *   double tap          -> private SOS: Noise-encrypted PM to each circle member
 *   single tap          -> nothing (accidental-press guard)
 * The on-board LED confirms which alert fired, and blinks briefly when a delivery
 * is first confirmed. Alerts are retried until delivered (see alert_retry.h);
 * 'sos status' shows where they are.
 */
#ifndef ALERTAM_H
#define ALERTAM_H

#include <zephyr/kernel.h>

/* Number of links a packet can be written to right now */
typedef int (*alertam_links_fn)(void);

int alertam_init(struct k_work_q *ble_q, alertam_links_fn links_ready);

/* A link just became usable (subscribed + announced) or the clock just got
 * synced: deliver pending alerts now. Call from the BLE work queue. */
void alertam_link_ready(void);

#endif /* ALERTAM_H */
```

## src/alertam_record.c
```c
/*
 * alertam_record.c - flash record encoding. See alertam_record.h.
 */
#include "alertam_record.h"

#include <string.h>

void arec_id_encode(uint8_t out[AREC_ID_LEN], const uint8_t noise_priv[32],
		    const uint8_t ed_seed[32])
{
	out[0] = AREC_VERSION;
	memcpy(out + 1, noise_priv, 32);
	memcpy(out + 33, ed_seed, 32);
}

int arec_id_decode(const uint8_t *in, size_t len, uint8_t noise_priv[32], uint8_t ed_seed[32])
{
	if (len != AREC_ID_LEN || in[0] != AREC_VERSION) {
		return -1;
	}
	memcpy(noise_priv, in + 1, 32);
	memcpy(ed_seed, in + 33, 32);
	return 0;
}

static int is_hex(char c)
{
	return (c >= '0' && c <= '9') || (c >= 'a' && c <= 'f');
}

int arec_circle_encode(uint8_t *out, size_t cap, const struct arec_member *m, int n)
{
	if (n < 0 || n > AREC_CIRCLE_MAX || cap < 2) {
		return -1;
	}
	size_t pos = 0;
	out[pos++] = AREC_VERSION;
	out[pos++] = (uint8_t)n;
	for (int i = 0; i < n; i++) {
		size_t nl = strnlen(m[i].name, AREC_NAME_LEN - 1);
		if (strlen(m[i].id_hex) != 16 || pos + 17 + nl > cap) {
			return -1;
		}
		memcpy(out + pos, m[i].id_hex, 16);
		pos += 16;
		out[pos++] = (uint8_t)nl;
		memcpy(out + pos, m[i].name, nl);
		pos += nl;
	}
	return (int)pos;
}

int arec_circle_decode(const uint8_t *in, size_t len, struct arec_member *m, int max)
{
	if (len < 2 || in[0] != AREC_VERSION || in[1] > AREC_CIRCLE_MAX) {
		return -1;
	}
	int n = in[1];
	size_t pos = 2;
	int out = 0;
	for (int i = 0; i < n; i++) {
		if (pos + 17 > len) {
			return -1;
		}
		const uint8_t *hex = in + pos;
		size_t nl = in[pos + 16];
		pos += 17;
		if (nl > AREC_NAME_LEN - 1 || pos + nl > len) {
			return -1;
		}
		for (int k = 0; k < 16; k++) {
			if (!is_hex((char)hex[k])) {
				return -1;
			}
		}
		if (out < max) {
			memcpy(m[out].id_hex, hex, 16);
			m[out].id_hex[16] = '\0';
			memcpy(m[out].name, in + pos, nl);
			m[out].name[nl] = '\0';
			out++;
		}
		pos += nl;
	}
	return pos == len ? out : -1;
}
```

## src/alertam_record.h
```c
/*
 * alertam_record.h - flash record encoding for Alertam settings (Zephyr-free,
 * host-testable; see tests/test_store.c)
 *
 * Records (settings keys under "alertam/", see alertam_store.h):
 *   id      1 version + 32 Noise X25519 private key + 32 Ed25519 seed  = 65 bytes
 *   circle  1 version + 1 count + count x (16 hex peer ID + 1 len + name) <= 202 bytes
 *   nick    raw nickname bytes (no NUL)
 *   sos     raw SOS text bytes (no NUL)
 */
#ifndef ALERTAM_RECORD_H
#define ALERTAM_RECORD_H

#include <stddef.h>
#include <stdint.h>

#define AREC_VERSION     1
#define AREC_ID_LEN      65
#define AREC_CIRCLE_MAX  5
#define AREC_NAME_LEN    24 /* incl. NUL */
#define AREC_CIRCLE_CAP  (2 + AREC_CIRCLE_MAX * (16 + 1 + AREC_NAME_LEN - 1))

struct arec_member {
	char name[AREC_NAME_LEN];
	char id_hex[17]; /* 16 lowercase hex + NUL */
};

void arec_id_encode(uint8_t out[AREC_ID_LEN], const uint8_t noise_priv[32],
		    const uint8_t ed_seed[32]);
/* Returns 0, or -1 if the record is malformed */
int arec_id_decode(const uint8_t *in, size_t len, uint8_t noise_priv[32], uint8_t ed_seed[32]);

/* Returns the encoded length, or -1 if n is out of range / cap too small */
int arec_circle_encode(uint8_t *out, size_t cap, const struct arec_member *m, int n);
/* Returns the number of members decoded (0..max), or -1 if malformed */
int arec_circle_decode(const uint8_t *in, size_t len, struct arec_member *m, int max);

#endif /* ALERTAM_RECORD_H */
```

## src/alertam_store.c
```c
/*
 * alertam_store.c - Alertam state persisted in flash. See alertam_store.h.
 */
#include "alertam_store.h"

#include <errno.h>
#include <string.h>
#include <zephyr/kernel.h>
#include <zephyr/settings/settings.h>
#include <zephyr/shell/shell.h>
#include <zephyr/sys/printk.h>
#include <zephyr/sys/reboot.h>
#include <psa/crypto.h>

#include "../lib/monocypher/monocypher.h"
#include "bitchat_wire.h"

#define SUBTREE "alertam"

static bool ready;

/* Values seen by the settings loader at boot (and kept in sync on save) */
static uint8_t id_rec[AREC_ID_LEN];
static bool have_id;
static char nick[bitchat_NICKNAME_LEN];
static char sos[200];
static uint8_t circle_rec[AREC_CIRCLE_CAP];
static int circle_len;

static int read_str(settings_read_cb read_cb, void *cb_arg, size_t len, char *buf, size_t cap)
{
	if (len == 0 || len >= cap) {
		return -EINVAL;
	}
	ssize_t n = read_cb(cb_arg, buf, len);
	if (n != (ssize_t)len) {
		buf[0] = '\0';
		return -EIO;
	}
	buf[n] = '\0';
	return 0;
}

static int h_set(const char *name, size_t len, settings_read_cb read_cb, void *cb_arg)
{
	const char *next;

	if (settings_name_steq(name, "id", &next) && !next) {
		if (len != sizeof(id_rec) || read_cb(cb_arg, id_rec, len) != (ssize_t)len) {
			return -EINVAL;
		}
		have_id = true;
		return 0;
	}
	if (settings_name_steq(name, "nick", &next) && !next) {
		return read_str(read_cb, cb_arg, len, nick, sizeof(nick));
	}
	if (settings_name_steq(name, "sos", &next) && !next) {
		return read_str(read_cb, cb_arg, len, sos, sizeof(sos));
	}
	if (settings_name_steq(name, "circle", &next) && !next) {
		if (len > sizeof(circle_rec) || read_cb(cb_arg, circle_rec, len) != (ssize_t)len) {
			circle_len = 0;
			return -EINVAL;
		}
		circle_len = (int)len;
		return 0;
	}
	return -ENOENT;
}

SETTINGS_STATIC_HANDLER_DEFINE(alertam, SUBTREE, NULL, h_set, NULL, NULL);

int astore_init(void)
{
	int ret = settings_subsys_init();
	if (ret == 0) {
		ret = settings_load_subtree(SUBTREE);
	}
	ready = ret == 0;
	if (!ready) {
		printk("[Store] settings init failed (%d): nothing will persist\n", ret);
	}
	return ret;
}

static int save(const char *key, const void *val, size_t len)
{
	if (!ready) {
		return -ENODEV;
	}
	char full[24];
	snprintk(full, sizeof(full), SUBTREE "/%s", key);
	int ret = settings_save_one(full, val, len);
	if (ret) {
		printk("[Store] save %s failed (%d)\n", full, ret);
	}
	return ret;
}

/* ---------- identity ---------- */

static int identity_new(struct bitchat_identity *id)
{
	uint8_t noise_priv[32], seed[32];
	if (psa_generate_random(noise_priv, sizeof(noise_priv)) != PSA_SUCCESS ||
	    psa_generate_random(seed, sizeof(seed)) != PSA_SUCCESS) {
		return -EIO;
	}
	arec_id_encode(id_rec, noise_priv, seed);
	have_id = true;
	int ret = bcw_identity_init_from(id, noise_priv, seed);
	crypto_wipe(noise_priv, sizeof(noise_priv));
	crypto_wipe(seed, sizeof(seed));
	if (ret) {
		return ret;
	}
	/* a failed save is not fatal: the identity still works until reboot */
	(void)save("id", id_rec, sizeof(id_rec));
	return 0;
}

int astore_identity_load(struct bitchat_identity *id, bool *created)
{
	uint8_t noise_priv[32], seed[32];

	*created = false;
	if (have_id && arec_id_decode(id_rec, sizeof(id_rec), noise_priv, seed) == 0) {
		int ret = bcw_identity_init_from(id, noise_priv, seed);
		crypto_wipe(noise_priv, sizeof(noise_priv));
		crypto_wipe(seed, sizeof(seed));
		return ret;
	}
	*created = true;
	return identity_new(id);
}

int astore_identity_regenerate(struct bitchat_identity *id)
{
	return identity_new(id);
}

/* ---------- nickname / SOS text / circle ---------- */

const char *astore_nick(void)
{
	return nick[0] ? nick : NULL;
}

int astore_save_nick(const char *name)
{
	strncpy(nick, name, sizeof(nick) - 1);
	nick[sizeof(nick) - 1] = '\0';
	return save("nick", nick, strlen(nick));
}

const char *astore_sos(void)
{
	return sos[0] ? sos : NULL;
}

int astore_save_sos(const char *text)
{
	strncpy(sos, text, sizeof(sos) - 1);
	sos[sizeof(sos) - 1] = '\0';
	return save("sos", sos, strlen(sos));
}

int astore_load_circle(struct arec_member *m, int max)
{
	if (circle_len == 0) {
		return 0;
	}
	int n = arec_circle_decode(circle_rec, (size_t)circle_len, m, max);
	if (n < 0) {
		printk("[Store] circle record malformed, ignored\n");
		return 0;
	}
	return n;
}

int astore_save_circle(const struct arec_member *m, int n)
{
	int len = arec_circle_encode(circle_rec, sizeof(circle_rec), m, n);
	if (len < 0) {
		return -EINVAL;
	}
	circle_len = len;
	return save("circle", circle_rec, (size_t)len);
}

/* ---------- factory reset ---------- */

static int cmd_alertam_reset(const struct shell *sh, size_t argc, char **argv)
{
	static const char *const keys[] = { "id", "nick", "circle", "sos" };

	if (argc < 2 || strcmp(argv[1], "confirm") != 0) {
		shell_print(sh, "Wipes identity (new peer ID), nickname, circle and SOS text, then reboots.");
		shell_print(sh, "Type 'alertam reset confirm' to proceed.");
		return -EINVAL;
	}
	int fails = 0;
	for (size_t i = 0; i < ARRAY_SIZE(keys); i++) {
		char full[24];
		snprintk(full, sizeof(full), SUBTREE "/%s", keys[i]);
		fails += ready && settings_delete(full) != 0;
	}
	shell_print(sh, "[Store] factory reset %s, rebooting...", fails ? "had errors" : "done");
	k_msleep(200);
	sys_reboot(SYS_REBOOT_COLD);
	return 0;
}

SHELL_STATIC_SUBCMD_SET_CREATE(sub_alertam,
	SHELL_CMD(reset, NULL, "confirm - Factory reset: wipe saved identity/circle/SOS text, reboot",
		  cmd_alertam_reset),
	SHELL_SUBCMD_SET_END
);
SHELL_CMD_REGISTER(alertam, &sub_alertam, "Alertam device settings", NULL);
```

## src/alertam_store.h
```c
/*
 * alertam_store.h - Alertam state persisted in flash
 *
 * Zephyr settings on ZMS, in the board's storage_partition. Keys:
 *   alertam/id      identity private material (Noise X25519 key + Ed25519 seed)
 *   alertam/nick    nickname
 *   alertam/circle  private SOS circle (peer ID + name per member)
 *   alertam/sos     SOS text
 * Record layouts: alertam_record.h.
 *
 * SECURITY: the private keys sit unencrypted in flash for now; ESP32 flash
 * encryption is a later hardening step. Never print them.
 *
 * If the backend fails to mount, everything keeps working from RAM (as before)
 * and the save functions return an error.
 */
#ifndef ALERTAM_STORE_H
#define ALERTAM_STORE_H

#include <stdbool.h>
#include "alertam_record.h"
#include "bitchat_protocol.h"

/* Mount the settings backend and load the "alertam" subtree. Call first in main. */
int astore_init(void);

/* Identity: load the persisted one, or generate + save a new one. Fills the keys
 * in id (via bcw_identity_init_from) and sets *created. Leaves id->nickname alone. */
int astore_identity_load(struct bitchat_identity *id, bool *created);
/* 'keys generate': fresh random identity, saved */
int astore_identity_regenerate(struct bitchat_identity *id);

/* Saved nickname, or NULL if none */
const char *astore_nick(void);
int astore_save_nick(const char *nick);

/* Saved SOS text, or NULL if none */
const char *astore_sos(void);
int astore_save_sos(const char *text);

/* Loads up to max members; returns the count (0 if none / malformed) */
int astore_load_circle(struct arec_member *m, int max);
int astore_save_circle(const struct arec_member *m, int n);

#endif /* ALERTAM_STORE_H */
```

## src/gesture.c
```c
/*
 * gesture.c - single-button gesture detection (Alertam). See gesture.h.
 */
#include "gesture.h"

#include <string.h>

void gesture_init(struct gesture_state *s)
{
	memset(s, 0, sizeof(*s));
}

const char *gesture_name(enum gesture g)
{
	switch (g) {
	case GESTURE_SINGLE: return "single";
	case GESTURE_DOUBLE: return "double";
	case GESTURE_LONG:   return "long";
	default:             return "none";
	}
}

enum gesture gesture_update(struct gesture_state *s, const struct gesture_cfg *cfg,
			    bool pressed, uint32_t now)
{
	/* Debounce: accept a new level only after it has been stable */
	if (pressed != s->raw) {
		s->raw = pressed;
		s->raw_since = now;
	}
	bool edge = false;
	if (s->raw != s->stable && now - s->raw_since >= cfg->debounce_ms) {
		s->stable = s->raw;
		edge = true;
	}

	if (edge && s->stable) {
		/* press */
		s->down_at = now;
		s->consumed = false;
		if (s->taps == 1 && now - s->last_up <= cfg->double_ms) {
			s->taps = 0;
			s->consumed = true; /* don't let this press also become LONG */
			return GESTURE_DOUBLE;
		}
		s->taps = 0;
		return GESTURE_NONE;
	}

	if (edge && !s->stable) {
		/* release */
		if (!s->consumed) {
			s->taps = 1;
			s->last_up = now;
		}
		s->consumed = false;
		return GESTURE_NONE;
	}

	if (s->stable && !s->consumed && now - s->down_at >= cfg->long_ms) {
		s->consumed = true;
		s->taps = 0;
		return GESTURE_LONG;
	}

	if (!s->stable && s->taps == 1 && now - s->last_up > cfg->double_ms) {
		s->taps = 0;
		return GESTURE_SINGLE;
	}
	return GESTURE_NONE;
}
```
